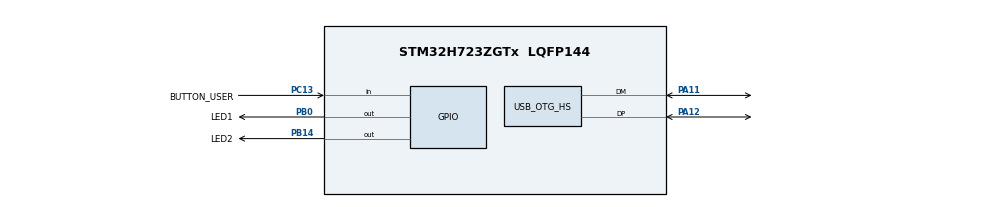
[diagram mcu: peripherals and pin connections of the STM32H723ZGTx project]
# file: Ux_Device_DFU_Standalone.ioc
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CORTEX_M7.AccessPermission-Cortex_Memory_Protection_Unit_Region0_Settings=MPU_REGION_FULL_ACCESS
CORTEX_M7.AccessPermission_S-Cortex_Memory_Protection_Unit_Region1_Settings_S=MPU_REGION_FULL_ACCESS
CORTEX_M7.AccessPermission_Spec=MPU_REGION_NO_ACCESS
CORTEX_M7.BaseAddress-Cortex_Memory_Protection_Unit_Region0_Settings=0x24035000
CORTEX_M7.BaseAddress_S-Cortex_Memory_Protection_Unit_Region1_Settings_S=0x24035000
CORTEX_M7.BaseAddress_Spec=0x0
CORTEX_M7.CPU_DCache=Enabled
CORTEX_M7.CPU_ICache=Enabled
CORTEX_M7.DisableExec_Spec=MPU_INSTRUCTION_ACCESS_DISABLE
CORTEX_M7.Enable-Cortex_Memory_Protection_Unit_Region0_Settings=MPU_REGION_ENABLE
CORTEX_M7.Enable_S-Cortex_Memory_Protection_Unit_Region1_Settings_S=MPU_REGION_ENABLE
CORTEX_M7.IsShareable_Spec=MPU_ACCESS_SHAREABLE
CORTEX_M7.MPU_Control=MPU_HFNMI_PRIVDEF
CORTEX_M7.Size-Cortex_Memory_Protection_Unit_Region0_Settings=MPU_REGION_SIZE_64KB
CORTEX_M7.Size_S-Cortex_Memory_Protection_Unit_Region1_Settings_S=MPU_REGION_SIZE_64KB
CORTEX_M7.Size_Spec=MPU_REGION_SIZE_4GB
CORTEX_M7.SubRegionDisable_Spec=0x87
CORTEX_M7.TypeExtField-Cortex_Memory_Protection_Unit_Region0_Settings=MPU_TEX_LEVEL1
CORTEX_M7.TypeExtField_S-Cortex_Memory_Protection_Unit_Region1_Settings_S=MPU_TEX_LEVEL1
CORTEX_M7.TypeExtField_Spec=MPU_TEX_LEVEL0
CORTEX_M7.default_mode_Activation=1
Mcu.Family=STM32H7
Mcu.Name=STM32H723ZGTx
Mcu.Package=LQFP144
NVIC.OTG_HS_IRQn=true\:7\:0\:true\:false\:true\:true\:true\:true
NVIC.PriorityGroup=NVIC_PRIORITYGROUP_4
PA11.Mode=Device_Only_FS
PA11.Signal=USB_OTG_HS_DM
PA12.Mode=Device_Only_FS
PA12.Signal=USB_OTG_HS_DP
PB0.GPIO_Label=LED1
PB0.GPIO_Speed=GPIO_SPEED_FREQ_VERY_HIGH
PB0.Signal=GPIO_Output
PB14.GPIO_Label=LED2
PB14.GPIO_Speed=GPIO_SPEED_FREQ_VERY_HIGH
PB14.Signal=GPIO_Output
PC13.GPIO_Label=BUTTON_USER
PC13.GPIO_PuPd=GPIO_PULLDOWN
PC13.Signal=GPIO_Input
PH0-OSC_IN.Mode=HSE-External-Clock-Source
PH0-OSC_IN.Signal=RCC_OSC_IN
PH1-OSC_OUT.Mode=HSE-External-Oscillator
PH1-OSC_OUT.Signal=RCC_OSC_OUT
ProjectManager.HeapSize=0x200
ProjectManager.StackSize=0x400
ProjectManager.TargetToolchain=MDK-ARM V5.32
RCC.ADCFreq_Value=16125000
RCC.APB1Freq_Value=130000000
RCC.APB2Freq_Value=130000000
RCC.APB3Freq_Value=130000000
RCC.APB4Freq_Value=130000000
RCC.CortexFreq_Value=520000000
RCC.D1PPRE=RCC_APB3_DIV2
RCC.D2PPRE1=RCC_APB1_DIV2
RCC.D2PPRE2=RCC_APB2_DIV2
RCC.D3PPRE=RCC_APB4_DIV2
RCC.DIVM1=4
RCC.DIVN1=260
RCC.DIVP1=1
RCC.HCLKFreq_Value=260000000
RCC.HPRE=RCC_HCLK_DIV2
RCC.HSE_VALUE=8000000
RCC.PLL2FRACN=0
RCC.PLL3FRACN=0
RCC.PLLFRACN=0
RCC.PLLSourceVirtual=RCC_PLLSOURCE_HSE
RCC.SYSCLKFreq_VALUE=520000000
RCC.SYSCLKSource=RCC_SYSCLKSOURCE_PLLCLK
RCC.SupplySource=PWR_LDO_SUPPLY
RCC.USBCLockSelection=RCC_USBCLKSOURCE_HSI48
RCC.USBFreq_Value=48000000
STMicroelectronics.X-CUBE-AZRTOS-H7.3.3.0.MEDIA_PROGRAM_TIME=5
STMicroelectronics.X-CUBE-AZRTOS-H7.3.3.0.REG_USBX_DEVICE_CON_CK=1
STMicroelectronics.X-CUBE-AZRTOS-H7.3.3.0.TX_DISABLE_PREEMPTION_THRESHOLD=1
STMicroelectronics.X-CUBE-AZRTOS-H7.3.3.0.USBD_COMPOSITE_USE_IAD=0
STMicroelectronics.X-CUBE-AZRTOS-H7.3.3.0.USBD_DEVICE_FRAMEWORK_BUILDER_ENABLED=1
STMicroelectronics.X-CUBE-AZRTOS-H7.3.3.0.USBD_DFU_MEDIA=@Internal Flash   /0x08000000/1*128Ka,7*128Kg
STMicroelectronics.X-CUBE-AZRTOS-H7.3.3.0.USBD_PID=0xdf11
STMicroelectronics.X-CUBE-AZRTOS-H7.3.3.0.USBD_PRODUCT_STRING=STM Device in DFU Mode
STMicroelectronics.X-CUBE-AZRTOS-H7.3.3.0.USBD_SERIAL_NUMBER=DFU001
STMicroelectronics.X-CUBE-AZRTOS-H7.3.3.0.USBXCcUSBJjUSBXJjCoreSystem=true
STMicroelectronics.X-CUBE-AZRTOS-H7.3.3.0.USBXCcUSBJjUSBXJjCoreUtilities=true
STMicroelectronics.X-CUBE-AZRTOS-H7.3.3.0.USBXCcUSBJjUSBXJjUXOoDeviceOoClassOoDFU=true
STMicroelectronics.X-CUBE-AZRTOS-H7.3.3.0.USBXCcUSBJjUSBXJjUXOoDeviceOoControllers=true
STMicroelectronics.X-CUBE-AZRTOS-H7.3.3.0.USBXCcUSBJjUSBXJjUXOoDeviceOoCoreStack=true
STMicroelectronics.X-CUBE-AZRTOS-H7.3.3.0.USBX_DEVICE_SYS_SIZE=3*1024
STMicroelectronics.X-CUBE-AZRTOS-H7.3.3.0.UX_DEVICE_APP_MEM_POOL_SIZE=7 *1024
STMicroelectronics.X-CUBE-AZRTOS-H7.3.3.0.UX_DEVICE_APP_MEM_POOL_SIZE_STANDLONE=3*1024
STMicroelectronics.X-CUBE-AZRTOS-H7.3.3.0.UX_DEVICE_CLASS_DFU_CUSTOM_REQUEST_ENABLE=1
STMicroelectronics.X-CUBE-AZRTOS-H7.3.3.0.UX_DEVICE_CLASS_DFU_ERROR_GET_ENABLE=1
STMicroelectronics.X-CUBE-AZRTOS-H7.3.3.0.UX_DEVICE_CLASS_DFU_STATUS_MODE=1
STMicroelectronics.X-CUBE-AZRTOS-H7.3.3.0.UX_DEVICE_SIDE_ONLY=1
STMicroelectronics.X-CUBE-AZRTOS-H7.3.3.0.UX_SLAVE_REQUEST_CONTROL_MAX_LENGTH=1024
STMicroelectronics.X-CUBE-AZRTOS-H7.3.3.0_IsAnAzureRtosMw=true
USB_OTG_HS.VirtualMode-Device_Only_FS=Device_Only_FS
VP_RCC_USB.Mode=USB_HS
VP_STMicroelectronics.X-CUBE-AZRTOS-H7_VS_USBJjUSBX_6.4.0_3.3.0.Mode=USBJjUSBX
board=custom

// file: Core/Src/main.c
/* USER CODE BEGIN Header */
/**
  ******************************************************************************
  * @file           : main.c
  * @brief          : Main program body
  ******************************************************************************
  * @attention
  *
  * Copyright (c) 2024 STMicroelectronics.
  * All rights reserved.
  *
  * This software is licensed under terms that can be found in the LICENSE file
  * in the root directory of this software component.
  * If no LICENSE file comes with this software, it is provided AS-IS.
  *
  ******************************************************************************
  */
/* USER CODE END Header */
#include "main.h"
#include "gpio.h"

void SystemClock_Config(void);
static void MPU_Config(void);

/* USER CODE BEGIN 0 */
typedef  void (*pFunction)(void);
/* USER CODE END 0 */

int main(void)
{

  /* USER CODE BEGIN 1 */
  pFunction JumpToApplication;
  uint32_t JumpAddress;
  /* USER CODE END 1 */

  /* MPU Configuration--------------------------------------------------------*/

  MPU_Config();

  /* Enable the CPU Cache */

  /* Enable I-Cache---------------------------------------------------------*/
  SCB_EnableICache();

  /* Enable D-Cache---------------------------------------------------------*/
  SCB_EnableDCache();

  /* MCU Configuration--------------------------------------------------------*/

  /* Reset of all peripherals, Initializes the Flash interface and the Systick. */
  HAL_Init();

  /* Configure the system clock */
  SystemClock_Config();

  /* Initialize all configured peripherals */
  MX_GPIO_Init();
  /* USER CODE BEGIN 2 */
  /* Unlock the Flash to enable the flash control register access */
  HAL_FLASH_Unlock();

  /* Check if the User push-button is pressed */
  if (HAL_GPIO_ReadPin(GPIOC, GPIO_PIN_13) == GPIO_PIN_RESET)
  {
    /* Test if user code is programmed starting from address 0x08020000 */
    if (((*(__IO uint32_t *) USBD_DFU_APP_DEFAULT_ADDR) & USBD_DFU_APP_MASK) ==
        USBD_DFU_APP_START_ADDR)
    {
      /*  Disable interrupts for timers */
      HAL_NVIC_DisableIRQ(TIM6_DAC_IRQn);

      /* Jump to user application */
      JumpAddress = *(__IO uint32_t *) (USBD_DFU_APP_DEFAULT_ADDR + 4);
      JumpToApplication = (pFunction) JumpAddress;

      /* Initialize user application's Stack Pointer */
      __set_MSP(*(__IO uint32_t *) USBD_DFU_APP_DEFAULT_ADDR);
      JumpToApplication();
    }
  }

  MX_USBX_Device_Init();

  /* USER CODE END 2 */

  /* Infinite loop */
  while (1)
  {

    /* USER CODE BEGIN 3 */
    USBX_Device_Process(NULL);
  }
  /* USER CODE END 3 */
}

void SystemClock_Config(void)
{
  RCC_OscInitTypeDef RCC_OscInitStruct = {0};
  RCC_ClkInitTypeDef RCC_ClkInitStruct = {0};
  RCC_CRSInitTypeDef RCC_CRSInitStruct = {0};

  /** Supply configuration update enable
  */
  HAL_PWREx_ConfigSupply(PWR_LDO_SUPPLY);

  /** Configure the main internal regulator output voltage
  */
  __HAL_PWR_VOLTAGESCALING_CONFIG(PWR_REGULATOR_VOLTAGE_SCALE0);

  while(!__HAL_PWR_GET_FLAG(PWR_FLAG_VOSRDY)) {}

  /** Initializes the RCC Oscillators according to the specified parameters
  * in the RCC_OscInitTypeDef structure.
  */
  RCC_OscInitStruct.OscillatorType = RCC_OSCILLATORTYPE_HSI48|RCC_OSCILLATORTYPE_HSE;
  RCC_OscInitStruct.HSEState = RCC_HSE_BYPASS;
  RCC_OscInitStruct.HSI48State = RCC_HSI48_ON;
  RCC_OscInitStruct.PLL.PLLState = RCC_PLL_ON;
  RCC_OscInitStruct.PLL.PLLSource = RCC_PLLSOURCE_HSE;
  RCC_OscInitStruct.PLL.PLLM = 4;
  RCC_OscInitStruct.PLL.PLLN = 260;
  RCC_OscInitStruct.PLL.PLLP = 1;
  RCC_OscInitStruct.PLL.PLLQ = 2;
  RCC_OscInitStruct.PLL.PLLR = 2;
  RCC_OscInitStruct.PLL.PLLRGE = RCC_PLL1VCIRANGE_1;
  RCC_OscInitStruct.PLL.PLLVCOSEL = RCC_PLL1VCOWIDE;
  RCC_OscInitStruct.PLL.PLLFRACN = 0;
  if (HAL_RCC_OscConfig(&RCC_OscInitStruct) != HAL_OK)
  {
    Error_Handler();
  }

  /** Initializes the CPU, AHB and APB buses clocks
  */
  RCC_ClkInitStruct.ClockType = RCC_CLOCKTYPE_HCLK|RCC_CLOCKTYPE_SYSCLK
                              |RCC_CLOCKTYPE_PCLK1|RCC_CLOCKTYPE_PCLK2
                              |RCC_CLOCKTYPE_D3PCLK1|RCC_CLOCKTYPE_D1PCLK1;
  RCC_ClkInitStruct.SYSCLKSource = RCC_SYSCLKSOURCE_PLLCLK;
  RCC_ClkInitStruct.SYSCLKDivider = RCC_SYSCLK_DIV1;
  RCC_ClkInitStruct.AHBCLKDivider = RCC_HCLK_DIV2;
  RCC_ClkInitStruct.APB3CLKDivider = RCC_APB3_DIV2;
  RCC_ClkInitStruct.APB1CLKDivider = RCC_APB1_DIV2;
  RCC_ClkInitStruct.APB2CLKDivider = RCC_APB2_DIV2;
  RCC_ClkInitStruct.APB4CLKDivider = RCC_APB4_DIV2;

  if (HAL_RCC_ClockConfig(&RCC_ClkInitStruct, FLASH_LATENCY_3) != HAL_OK)
  {
    Error_Handler();
  }

  /** Enable the SYSCFG APB clock
  */
  __HAL_RCC_CRS_CLK_ENABLE();

  /** Configures CRS
  */
  RCC_CRSInitStruct.Prescaler = RCC_CRS_SYNC_DIV1;
  RCC_CRSInitStruct.Source = RCC_CRS_SYNC_SOURCE_USB2;
  RCC_CRSInitStruct.Polarity = RCC_CRS_SYNC_POLARITY_RISING;
  RCC_CRSInitStruct.ReloadValue = __HAL_RCC_CRS_RELOADVALUE_CALCULATE(48000000,1000);
  RCC_CRSInitStruct.ErrorLimitValue = 34;
  RCC_CRSInitStruct.HSI48CalibrationValue = 32;

  HAL_RCCEx_CRSConfig(&RCC_CRSInitStruct);
}

 /* MPU Configuration */

void MPU_Config(void)
{
  MPU_Region_InitTypeDef MPU_InitStruct = {0};

  /* Disables the MPU */
  HAL_MPU_Disable();

  /** Initializes and configures the Region and the memory to be protected
  */
  MPU_InitStruct.Enable = MPU_REGION_ENABLE;
  MPU_InitStruct.Number = MPU_REGION_NUMBER0;
  MPU_InitStruct.BaseAddress = 0x0;
  MPU_InitStruct.Size = MPU_REGION_SIZE_4GB;
  MPU_InitStruct.SubRegionDisable = 0x87;
  MPU_InitStruct.TypeExtField = MPU_TEX_LEVEL0;
  MPU_InitStruct.AccessPermission = MPU_REGION_NO_ACCESS;
  MPU_InitStruct.DisableExec = MPU_INSTRUCTION_ACCESS_DISABLE;
  MPU_InitStruct.IsShareable = MPU_ACCESS_SHAREABLE;
  MPU_InitStruct.IsCacheable = MPU_ACCESS_NOT_CACHEABLE;
  MPU_InitStruct.IsBufferable = MPU_ACCESS_NOT_BUFFERABLE;

  HAL_MPU_ConfigRegion(&MPU_InitStruct);

  /** Initializes and configures the Region and the memory to be protected
  */
  MPU_InitStruct.Number = MPU_REGION_NUMBER1;
  MPU_InitStruct.BaseAddress = 0x24035000;
  MPU_InitStruct.Size = MPU_REGION_SIZE_64KB;
  MPU_InitStruct.SubRegionDisable = 0x0;
  MPU_InitStruct.TypeExtField = MPU_TEX_LEVEL1;
  MPU_InitStruct.AccessPermission = MPU_REGION_FULL_ACCESS;
  MPU_InitStruct.DisableExec = MPU_INSTRUCTION_ACCESS_ENABLE;
  MPU_InitStruct.IsShareable = MPU_ACCESS_NOT_SHAREABLE;

  HAL_MPU_ConfigRegion(&MPU_InitStruct);
  /* Enables the MPU */
  HAL_MPU_Enable(MPU_HFNMI_PRIVDEF);

}

void Error_Handler(void)
{
  while (1)
  {
  }
}
